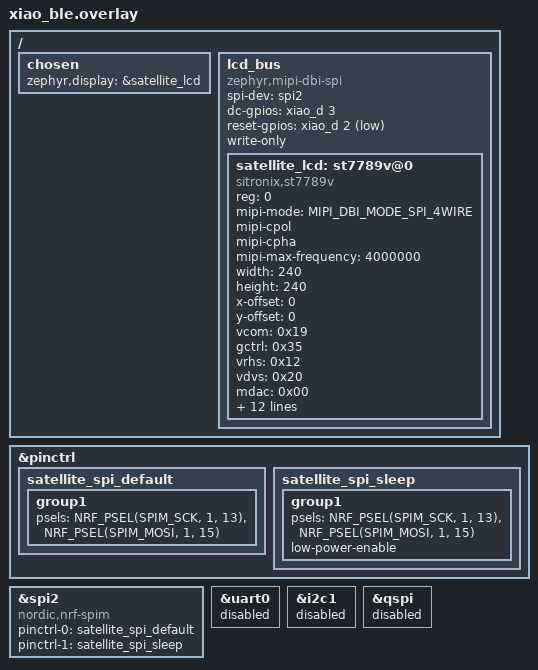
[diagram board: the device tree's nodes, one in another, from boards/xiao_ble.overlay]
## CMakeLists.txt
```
cmake_minimum_required(VERSION 3.20.0)
set(SATELLITE_STAGE "status" CACHE STRING "display, ble, or status")
if(SATELLITE_STAGE STREQUAL "ble")
  list(APPEND EXTRA_CONF_FILE "${CMAKE_CURRENT_SOURCE_DIR}/config/ble.conf")
  list(APPEND EXTRA_CONF_FILE "${CMAKE_CURRENT_SOURCE_DIR}/config/bluetooth.conf")
elseif(SATELLITE_STAGE STREQUAL "display" OR SATELLITE_STAGE STREQUAL "status")
  list(APPEND EXTRA_CONF_FILE "${CMAKE_CURRENT_SOURCE_DIR}/config/lvgl.conf")
  if(SATELLITE_STAGE STREQUAL "display")
    list(APPEND EXTRA_CONF_FILE "${CMAKE_CURRENT_SOURCE_DIR}/config/display.conf")
  else()
    list(APPEND EXTRA_CONF_FILE "${CMAKE_CURRENT_SOURCE_DIR}/config/bluetooth.conf")
  endif()
else()
  message(FATAL_ERROR "SATELLITE_STAGE must be display, ble or status")
endif()
find_package(Zephyr REQUIRED HINTS $ENV{ZEPHYR_BASE})
project(zmk_satellite VERSION 0.1.0 LANGUAGES C)
target_include_directories(app PRIVATE src)
target_sources(app PRIVATE src/main.c src/protocol.c src/state.c)
target_sources_ifdef(CONFIG_SATELLITE_BLE app PRIVATE src/scanner.c)
target_sources_ifdef(CONFIG_SATELLITE_DISPLAY app PRIVATE src/ui.c)
```

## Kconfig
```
mainmenu "ZMK Satellite"
source "Kconfig.zephyr"

config SATELLITE_DISPLAY
    bool "Enable ST7789 / LVGL display"
    default y
    select DISPLAY
    select LVGL

config SATELLITE_BLE
    bool "Receive Prospector-compatible advertisements"
    default y
    select BT
    select BT_OBSERVER

config SATELLITE_DISPLAY_TEST
    bool "Show color, border and simulated-state test (no live BLE)"
    default n
    depends on SATELLITE_DISPLAY && !SATELLITE_BLE

config SATELLITE_CHANNEL
    int "Prospector scanner channel (0 or >=10 accepts all, upstream semantics)"
    range 0 255
    default 0

config SATELLITE_KEYBOARD_ID
    string "Optional keyboard ID, 8 hexadecimal characters in wire order"
    default ""

config SATELLITE_KEYBOARD_NAME
    string "Optional display name override (ASCII)"
    default ""
    help
      Normally the keyboard name is learned from its BLE name advertisements.
      Set this only for a local display alias; it does not change the keyboard.

config SATELLITE_TIMEOUT_MS
    int "Advertisement silence timeout (must exceed keyboard idle interval)"
    range 1000 3600000
    default 95000
```

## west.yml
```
manifest:
  version: "0.13"
  self:
    path: zmk-satellite
  projects:
    - name: zephyr
      url: https://github.com/zephyrproject-rtos/zephyr
      revision: 7823374e872145b5bd018bfe447839eb36042611 # v4.1.0
      import:
        name-allowlist: [cmsis, cmsis_6, hal_nordic, lvgl, segger]
```

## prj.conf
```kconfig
CONFIG_MAIN_STACK_SIZE=4096
CONFIG_HEAP_MEM_POOL_SIZE=2048
CONFIG_LOG=y
CONFIG_LOG_MODE_DEFERRED=y
CONFIG_LOG_BUFFER_SIZE=4096
CONFIG_SERIAL=y
CONFIG_CONSOLE=y
CONFIG_UART_CONSOLE=y
CONFIG_USB_DEVICE_STACK=y
CONFIG_USB_CDC_ACM=y
CONFIG_USB_DEVICE_PRODUCT="ZMK Satellite"
CONFIG_USB_DEVICE_INITIALIZE_AT_BOOT=n
CONFIG_SPI=y
CONFIG_GPIO=y
CONFIG_ASSERT=y
```

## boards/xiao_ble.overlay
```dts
/*
 * SPDX-License-Identifier: Apache-2.0
 * ST7789 initialization values adapted from Zephyr's
 * st7789v_waveshare_240x240.overlay:
 * Copyright (c) 2019 Jan Van Winkel <jan.van_winkel@dxplore.eu>
 * Copyright (c) 2019 PHYTEC Messtechnik GmbH
 * SPI mode 3; no CS line (verified on the prototype panel). This bus must be dedicated to this panel.
 */
#include <zephyr/dt-bindings/gpio/gpio.h>
#include <zephyr/dt-bindings/pinctrl/nrf-pinctrl.h>
#include <zephyr/dt-bindings/mipi_dbi/mipi_dbi.h>

/ {
    chosen { zephyr,display = &satellite_lcd; };
    lcd_bus {
        compatible = "zephyr,mipi-dbi-spi";
        spi-dev = <&spi2>;
        dc-gpios = <&xiao_d 3 GPIO_ACTIVE_HIGH>;
        reset-gpios = <&xiao_d 2 GPIO_ACTIVE_LOW>;
        write-only;
        #address-cells = <1>;
        #size-cells = <0>;
        satellite_lcd: st7789v@0 {
            compatible = "sitronix,st7789v";
            reg = <0>;
            mipi-mode = "MIPI_DBI_MODE_SPI_4WIRE";
            mipi-cpol;
            mipi-cpha;
            mipi-max-frequency = <4000000>;
            width = <240>; height = <240>;
            x-offset = <0>; y-offset = <0>;
            vcom = <0x19>; gctrl = <0x35>;
            vrhs = <0x12>; vdvs = <0x20>;
            mdac = <0x00>; gamma = <0x01>;
            colmod = <0x05>; lcm = <0x2c>;
            porch-param = [0c 0c 00 33 33];
            cmd2en-param = [5a 69 02 01];
            pwctrl1-param = [a4 a1];
            pvgam-param = [d0 04 0d 11 13 2b 3f 54 4c 18 0d 0b 1f 23];
            nvgam-param = [d0 04 0c 11 13 2c 3f 44 51 2f 1f 1f 20 23];
            ram-param = [00 f8]; /* LVGL native little-endian RGB565 */ rgb-param = [cd 08 14];
        };
    };
};
&pinctrl {
    satellite_spi_default: satellite_spi_default {
        group1 { psels = <NRF_PSEL(SPIM_SCK, 1, 13)>,
                         <NRF_PSEL(SPIM_MOSI, 1, 15)>; };
    };
    satellite_spi_sleep: satellite_spi_sleep {
        group1 { psels = <NRF_PSEL(SPIM_SCK, 1, 13)>,
                         <NRF_PSEL(SPIM_MOSI, 1, 15)>;
                 low-power-enable; };
    };
};
&spi2 {
    compatible = "nordic,nrf-spim";
    status = "okay";
    pinctrl-0 = <&satellite_spi_default>;
    pinctrl-1 = <&satellite_spi_sleep>;
    pinctrl-names = "default", "sleep";
    /delete-property/ cs-gpios;
};
&uart0 { status = "disabled"; };
&i2c1 { status = "disabled"; };
&qspi { status = "disabled"; };
```

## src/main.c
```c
/* SPDX-License-Identifier: MIT */
#include "state.h"
#include <zephyr/kernel.h>
#include <zephyr/logging/log.h>
#include <zephyr/usb/usb_device.h>
#include <string.h>
#include <stdio.h>
#ifdef CONFIG_SATELLITE_BLE
#include "scanner.h"
#endif
#ifdef CONFIG_SATELLITE_DISPLAY
#include "ui.h"
#endif
LOG_MODULE_REGISTER(satellite, LOG_LEVEL_INF);

int main(void)
{
    int ret = usb_enable(NULL); /* Never wait for a host/DTR: USB-C power bank works. */
    if (ret) LOG_WRN("USB console unavailable: %d", ret);
    bool fatal = false;
    uint8_t filter[4];
    const uint8_t *filter_id = NULL;
    if (strlen(CONFIG_SATELLITE_KEYBOARD_ID)) {
        if (!sat_parse_id(CONFIG_SATELLITE_KEYBOARD_ID, filter)) {
            LOG_ERR("Invalid SATELLITE_KEYBOARD_ID (expected 8 hex chars)");
            fatal = true;
        } else filter_id = filter;
    }
#ifdef CONFIG_SATELLITE_DISPLAY
    ret = sat_ui_init();
    if (ret) { LOG_ERR("Display failed: %d", ret); return ret; }
    if (fatal) sat_ui_error("Invalid keyboard ID");
#endif
#ifdef CONFIG_SATELLITE_BLE
    if (!fatal) {
        ret = sat_scanner_start();
        if (ret) {
            LOG_ERR("BLE scan failed: %d", ret);
#ifdef CONFIG_SATELLITE_DISPLAY
            sat_ui_error("BLE start failed");
#endif
            fatal = true;
        }
    }
#endif
    struct sat_state state = {0};
    int64_t next_update = 0;
#ifdef CONFIG_SATELLITE_BLE
    int64_t next_diagnostics = 0;
#else
    ARG_UNUSED(filter_id);
#endif
    bool was_online = false;
    while (true) {
        int64_t now = k_uptime_get();
#ifdef CONFIG_SATELLITE_BLE
        struct sat_rx rx;
        if (now >= next_diagnostics) {
            LOG_INF("Scanning active; queue drops=%u", sat_scanner_dropped());
            next_diagnostics = now + 10000;
        }
        /* Bounded drain: a crowded RF environment cannot starve the display. */
        for (unsigned i = 0; !fatal && i < 16 && sat_scanner_take(&rx); ++i) {
            if (sat_update(&state, &rx.packet, rx.rssi, rx.time,
                           CONFIG_SATELLITE_CHANNEL, filter_id)) {
                if (rx.keyboard_name[0])
                    memcpy(state.keyboard_name, rx.keyboard_name, sizeof(state.keyboard_name));
                LOG_INF("ID=%02X%02X%02X%02X L=%u R=%u layer=%u(%s) BT=%u flags=%02x RSSI=%d",
                    rx.packet.id[0], rx.packet.id[1], rx.packet.id[2], rx.packet.id[3],
                    rx.packet.battery_left, rx.packet.battery_right, rx.packet.layer,
                    rx.packet.layer_name, rx.packet.profile + 1, rx.packet.flags, rx.rssi);
            }
        }
#endif
#ifdef CONFIG_SATELLITE_DISPLAY_TEST
        struct sat_packet p = {.version = 0x22, .battery_left = 76,
            .battery_right = 65, .role = 1, .profile = 2, .flags = 0x10,
            .layer = (now / 3000) % 5, .id = {0x12,0x34,0x56,0x78}};
        const char *demo_layers[] = {"BASE", "NAV", "NUM", "ADJ", "Auto"};
        snprintf(p.layer_name, sizeof(p.layer_name), "%s", demo_layers[p.layer]);
        const uint8_t demo_flags[] = {0x30, 0x20, 0x00, 0x08, 0x38};
        p.flags = demo_flags[(now / 3000) % 5];
        memcpy(state.keyboard_name, "Demo board", 11);
        /* 15s live simulation, then simulated loss; repeats every 25s. */
        if (now % 25000 < 15000)
            sat_update(&state, &p, -48, now, 0, NULL);
#endif
        if (now >= next_update && !fatal) {
            bool online = sat_online(&state, now, CONFIG_SATELLITE_TIMEOUT_MS);
            if (was_online && !online) LOG_WRN("Advertisement timeout; values are stale");
            was_online = online;
#ifdef CONFIG_SATELLITE_DISPLAY
            sat_ui_update(&state, now);
#endif
            next_update = now + 250;
        }
#ifdef CONFIG_SATELLITE_DISPLAY
        sat_ui_tick(); /* LVGL is owned exclusively by this thread. */
#endif
        k_sleep(K_MSEC(10));
    }
    return 0;
}
```

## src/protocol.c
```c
/* SPDX-License-Identifier: MIT */
#include "protocol.h"
#include <string.h>

bool sat_decode(const uint8_t *d, size_t n, struct sat_packet *out)
{
    if (!d || !out || n < SAT_PAYLOAD_SIZE || d[0] != 0xff || d[1] != 0xff ||
        d[2] != 0xab || d[3] != 0xcd) return false;
    /* v1 legacy or module-major 2. Future majors require a protocol review. */
    if (d[4] != 1 && (d[4] >> 4) != 2) return false;
    if (d[10] > 1 || (d[7] & 7) > 4) return false; /* ignore split peripherals */
    struct sat_packet p = {
        .version = d[4], .battery_left = d[5], .battery_right = d[12],
        .layer = d[6], .profile = d[7] & 7, .patch = (d[7] >> 3) & 7,
        .dev = (d[7] & 0x40) != 0, .connections = d[8], .flags = d[9],
        .role = d[10], .index = d[11], .aux = {d[13], d[14]},
        .modifiers = d[23], .wpm = d[24], .channel = d[25],
    };
    memcpy(p.id, d + 19, 4);
    /* Built-in font is ASCII. Do not let partial UTF-8/control bytes reach LVGL. */
    for (size_t i = 0; i < 4; ++i)
        p.layer_name[i] = d[15+i] == 0 ? 0 :
                            (d[15+i] >= 32 && d[15+i] <= 126 ? d[15+i] : '?');
    p.layer_name[4] = 0;
    *out = p;
    return true;
}

bool sat_parse_ad(const uint8_t *d, size_t n, struct sat_packet *out)
{
    if (!d || !out) return false;
    while (n) {
        size_t field = *d++;
        --n;
        if (!field) break;
        if (field > n) return false;
        if (d[0] == 0xff && sat_decode(d + 1, field - 1, out)) return true;
        d += field;
        n -= field;
    }
    return false;
}

bool sat_channel_matches(uint8_t scanner, uint8_t keyboard)
{
    return scanner == 0 || scanner >= 10 || keyboard == 0 || scanner == keyboard;
}

static int hex(char c)
{
    if (c >= '0' && c <= '9') return c - '0';
    if (c >= 'a' && c <= 'f') return c - 'a' + 10;
    if (c >= 'A' && c <= 'F') return c - 'A' + 10;
    return -1;
}

bool sat_parse_id(const char *s, uint8_t out[4])
{
    uint8_t id[4];
    if (!s || !out || strlen(s) != 8) return false;
    for (unsigned i = 0; i < 4; ++i) {
        int a = hex(s[i*2]), b = hex(s[i*2+1]);
        if (a < 0 || b < 0) return false;
        id[i] = (uint8_t)((a << 4) | b);
    }
    memcpy(out, id, 4);
    return true;
}

/* Names are separate AD reports. Keep parsing independent of the Bluetooth stack. */
bool sat_parse_name(const uint8_t *d, size_t n, char out[SAT_NAME_SIZE])
{
    if (!d || !out) return false;
    char name[SAT_NAME_SIZE] = {0};
    bool found = false, complete = false;
    while (n) {
        size_t field = *d++;
        --n;
        if (!field) break;
        if (field > n) return false;
        if ((d[0] == 0x08 || d[0] == 0x09) && field > 1 &&
            (!complete || d[0] == 0x09)) {
            size_t used = 0;
            for (size_t i = 1; i < field && used < SAT_NAME_SIZE - 1; ++i) {
                uint8_t c = d[i];
                if (!c) break;
                if (i + 2 < field && c == 0xef && d[i+1] == 0xbc && d[i+2] == 0xbf) {
                    name[used++] = '_'; /* Full-width underscore, common in keyboard names. */
                    i += 2;
                } else if (c >= 0x80) {
                    name[used++] = '?';
                    while (i + 1 < field && (d[i+1] & 0xc0) == 0x80) ++i;
                } else name[used++] = c >= 32 && c <= 126 ? (char)c : '?';
            }
            name[used] = 0;
            found = used > 0;
            complete = d[0] == 0x09;
        }
        d += field;
        n -= field;
    }
    if (found) memcpy(out, name, SAT_NAME_SIZE);
    return found;
}

enum sat_host_status sat_host_from_flags(uint8_t flags)
{
    bool usb = (flags & 0x08) != 0; /* HID-ready, not merely USB power. */
    bool ble = (flags & 0x10) != 0;
    return usb ? (ble ? SAT_HOST_BOTH : SAT_HOST_USB) :
                 (ble ? SAT_HOST_BLE : SAT_HOST_OFFLINE);
}

enum sat_bt_status sat_bt_from_flags(uint8_t flags)
{
    if (flags & 0x10) return SAT_BT_CONNECTED;
    return flags & 0x20 ? SAT_BT_PAIRED : SAT_BT_UNPAIRED;
}
```

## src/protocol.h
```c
/* SPDX-License-Identifier: MIT */
#pragma once
#include <stdbool.h>
#include <stddef.h>
#include <stdint.h>

#define SAT_PAYLOAD_SIZE 26
#define SAT_NAME_SIZE 32
enum sat_host_status { SAT_HOST_OFFLINE, SAT_HOST_BLE, SAT_HOST_USB, SAT_HOST_BOTH };
enum sat_host_status sat_host_from_flags(uint8_t flags);
enum sat_bt_status { SAT_BT_UNPAIRED, SAT_BT_PAIRED, SAT_BT_CONNECTED };
enum sat_bt_status sat_bt_from_flags(uint8_t flags);
bool sat_parse_name(const uint8_t *data, size_t len, char out[SAT_NAME_SIZE]);
struct sat_packet {
    uint8_t version, battery_left, battery_right, layer, profile;
    uint8_t connections, flags, role, index, aux[2], id[4];
    uint8_t modifiers, wpm, channel, patch;
    bool dev;
    char layer_name[5];
};
/* Decode bytes explicitly, without packed-struct casts or alignment assumptions. */
bool sat_decode(const uint8_t *data, size_t len, struct sat_packet *out);
bool sat_parse_ad(const uint8_t *data, size_t len, struct sat_packet *out);
bool sat_channel_matches(uint8_t scanner, uint8_t keyboard);
bool sat_parse_id(const char *text, uint8_t out[4]);
```

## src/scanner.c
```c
/* SPDX-License-Identifier: MIT */
#include "scanner.h"
#include <string.h>
#include <zephyr/kernel.h>
#include <zephyr/bluetooth/bluetooth.h>
#include <zephyr/sys/atomic.h>
#include <zephyr/logging/log.h>
LOG_MODULE_REGISTER(sat_scan, LOG_LEVEL_INF);
K_MSGQ_DEFINE(rx_queue, sizeof(struct sat_rx), 16, 8);
static atomic_t dropped;

/* Only valid status senders get cache entries; unrelated name beacons cannot evict them. */
static struct {
    bt_addr_le_t address;
    uint8_t id[4];
    char name[SAT_NAME_SIZE];
    int64_t last_seen;
    bool used;
} names[8];

static void receive(const bt_addr_le_t *addr, int8_t rssi, uint8_t type,
                    struct net_buf_simple *buf)
{
    ARG_UNUSED(type);
    struct sat_rx rx = {.rssi = rssi, .time = k_uptime_get()};
    bool packet = sat_parse_ad(buf->data, buf->len, &rx.packet) &&
        sat_channel_matches(CONFIG_SATELLITE_CHANNEL, rx.packet.channel);
    int entry = -1, oldest = 0;
    for (unsigned i = 0; i < ARRAY_SIZE(names); ++i) {
        if (names[i].used && !bt_addr_le_cmp(addr, &names[i].address)) entry = i;
        if (!names[i].used || names[i].last_seen < names[oldest].last_seen) oldest = i;
    }
    if (packet) {
        if (entry < 0) entry = oldest;
        if (!names[entry].used || bt_addr_le_cmp(addr, &names[entry].address) ||
            memcmp(names[entry].id, rx.packet.id, 4)) {
            memset(&names[entry], 0, sizeof(names[entry]));
            bt_addr_le_copy(&names[entry].address, addr);
            memcpy(names[entry].id, rx.packet.id, 4);
            names[entry].used = true;
        }
    }
    if (entry >= 0) {
        char name[SAT_NAME_SIZE];
        if (sat_parse_name(buf->data, buf->len, name))
            memcpy(names[entry].name, name, sizeof(name));
        names[entry].last_seen = rx.time;
    }
    if (packet) {
        memcpy(rx.keyboard_name, names[entry].name, sizeof(rx.keyboard_name));
        /* UI/state updates remain exclusively on the main thread. */
        if (k_msgq_put(&rx_queue, &rx, K_NO_WAIT)) atomic_inc(&dropped);
    }
}
int sat_scanner_start(void)
{
    int ret = bt_enable(NULL);
    if (ret) return ret;
    const struct bt_le_scan_param params = {
        .type = BT_LE_SCAN_TYPE_ACTIVE,
        .options = BT_LE_SCAN_OPT_NONE,
        .interval = 0x60, .window = 0x60,
    };
    return bt_le_scan_start(&params, receive);
}
bool sat_scanner_take(struct sat_rx *rx) { return k_msgq_get(&rx_queue, rx, K_NO_WAIT) == 0; }
unsigned sat_scanner_dropped(void) { return (unsigned)atomic_get(&dropped); }
```

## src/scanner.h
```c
#pragma once
#include "state.h"
struct sat_rx { struct sat_packet packet; int8_t rssi; int64_t time; char keyboard_name[SAT_NAME_SIZE]; };
int sat_scanner_start(void);
bool sat_scanner_take(struct sat_rx *rx);
unsigned sat_scanner_dropped(void);
```

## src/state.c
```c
/* SPDX-License-Identifier: MIT */
#include "state.h"
#include <string.h>
bool sat_online(const struct sat_state *s, int64_t now, int64_t timeout)
{
    return s->seen && now >= s->last_seen && now - s->last_seen < timeout;
}
bool sat_update(struct sat_state *s, const struct sat_packet *p, int8_t rssi,
                int64_t now, uint8_t channel, const uint8_t *filter_id)
{
    if (!sat_channel_matches(channel, p->channel)) return false;
    if (filter_id && memcmp(filter_id, p->id, 4)) return false;
    if (s->seen && memcmp(s->packet.id, p->id, 4)) return false;
    s->packet = *p;
    s->rssi = rssi;
    s->last_seen = now;
    s->seen = true;
    return true;
}
```

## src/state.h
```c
/* SPDX-License-Identifier: MIT */
#pragma once
#include "protocol.h"
struct sat_state {
    struct sat_packet packet;
    int64_t last_seen;
    int8_t rssi;
    bool seen;
    char keyboard_name[SAT_NAME_SIZE];
};
bool sat_online(const struct sat_state *s, int64_t now, int64_t timeout);
/* First ID stays selected, including after timeout. No mixing adjacent keyboards. */
bool sat_update(struct sat_state *s, const struct sat_packet *p, int8_t rssi,
                int64_t now, uint8_t channel, const uint8_t *filter_id);
```

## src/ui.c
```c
/* SPDX-License-Identifier: MIT */
#include "ui.h"
#include <stdio.h>
#include <errno.h>
#include <zephyr/device.h>
#include <zephyr/drivers/display.h>
#include <lvgl.h>
#include <lvgl_zephyr.h>

#define INK 0xe8eff3
#define DIM 0x9aafbb
#define CYAN 0x68bdd5
#define WARN 0xffb66e
#define USB_COLOR 0xf3bb76

static lv_obj_t *name, *status, *layer_number, *host, *host_icon, *endpoint_row;
static lv_obj_t *battery[2], *unit[2], *ring[2];

static lv_obj_t *label(lv_obj_t *parent, const char *text, int x, int y, int w,
                       const lv_font_t *font, uint32_t color)
{
    lv_obj_t *obj = lv_label_create(parent);
    lv_obj_set_pos(obj, x, y);
    lv_obj_set_width(obj, w);
    lv_label_set_long_mode(obj, LV_LABEL_LONG_DOT);
    lv_obj_set_style_text_font(obj, font, 0);
    lv_obj_set_style_text_color(obj, lv_color_hex(color), 0);
    lv_label_set_text(obj, text);
    return obj;
}

static lv_obj_t *center_label(lv_obj_t *parent, const char *text, int x, int y,
                              int w, const lv_font_t *font, uint32_t color)
{
    lv_obj_t *obj = label(parent, text, x, y, w, font, color);
    lv_obj_set_style_text_align(obj, LV_TEXT_ALIGN_CENTER, 0);
    return obj;
}

static lv_obj_t *battery_ring(lv_obj_t *screen, int x)
{
    lv_obj_t *obj = lv_arc_create(screen);
    lv_obj_remove_style_all(obj);
    lv_obj_set_pos(obj, x, 90);
    lv_obj_set_size(obj, 88, 88);
    lv_obj_remove_flag(obj, LV_OBJ_FLAG_CLICKABLE | LV_OBJ_FLAG_SCROLLABLE);
    lv_obj_set_style_arc_width(obj, 4, LV_PART_MAIN);
    lv_obj_set_style_arc_color(obj, lv_color_hex(0x30434e), LV_PART_MAIN);
    lv_obj_set_style_arc_opa(obj, LV_OPA_COVER, LV_PART_MAIN);
    lv_obj_set_style_arc_rounded(obj, false, LV_PART_MAIN);
    lv_obj_set_style_arc_width(obj, 4, LV_PART_INDICATOR);
    lv_obj_set_style_arc_color(obj, lv_color_hex(CYAN), LV_PART_INDICATOR);
    lv_obj_set_style_arc_opa(obj, LV_OPA_COVER, LV_PART_INDICATOR);
    lv_obj_set_style_arc_rounded(obj, false, LV_PART_INDICATOR);
    /* Full circle, clockwise from twelve o'clock. Zero has no indicator. */
    lv_arc_set_bg_angles(obj, 0, 360);
    lv_arc_set_rotation(obj, 270);
    lv_arc_set_range(obj, 0, 100);
    lv_arc_set_value(obj, 0);
    return obj;
}

int sat_ui_init(void)
{
    const struct device *dev = DEVICE_DT_GET(DT_CHOSEN(zephyr_display));
    if (!device_is_ready(dev)) return -ENODEV;
    int ret = lvgl_init();
    if (ret) return ret;
    lv_obj_t *screen = lv_screen_active();
    lv_obj_set_style_bg_color(screen, lv_color_hex(0x0d1820), 0);
    lv_obj_set_style_bg_opa(screen, LV_OPA_COVER, 0);
    lv_obj_set_style_border_width(screen, 0, 0);
    lv_obj_set_style_pad_all(screen, 0, 0);
    lv_obj_remove_flag(screen, LV_OBJ_FLAG_SCROLLABLE);
    lv_obj_t *brand = label(screen, "ZMK SATELLITE", 14, 14, 212,
                            &lv_font_montserrat_10, DIM);
    lv_obj_set_style_text_letter_space(brand, 1, 0);
    name = label(screen, "Keyboard", 14, 35, 212, &lv_font_montserrat_24, INK);

    /* Shared column centres at x=64 and x=176. */
    for (unsigned i = 0; i < 2; ++i) {
        int x = i ? 124 : 12;
        center_label(screen, i ? "RIGHT" : "LEFT", x, 76, 104,
                     &lv_font_montserrat_10, 0xa5b7c1);
        ring[i] = battery_ring(screen, x + 8);
        battery[i] = center_label(screen, "--", x + 10, 109, 84,
                                  &lv_font_montserrat_36, INK);
        unit[i] = center_label(screen, "%", x + 10, 148, 84,
                               &lv_font_montserrat_12, 0xa5b7c1);
        lv_obj_add_flag(unit[i], LV_OBJ_FLAG_HIDDEN);
    }

    center_label(screen, "LAYER", 12, 190, 104, &lv_font_montserrat_10, 0xa5b7c1);
    layer_number = center_label(screen, "--", 12, 204, 104,
                                &lv_font_montserrat_24, INK);
    status = center_label(screen, "WAITING", 124, 190, 104,
                          &lv_font_montserrat_10, CYAN);
    endpoint_row = lv_obj_create(screen);
    lv_obj_remove_style_all(endpoint_row);
    lv_obj_set_pos(endpoint_row, 124, 203);
    lv_obj_set_size(endpoint_row, 104, 29);
    lv_obj_remove_flag(endpoint_row, LV_OBJ_FLAG_SCROLLABLE | LV_OBJ_FLAG_CLICKABLE);
    lv_obj_set_flex_flow(endpoint_row, LV_FLEX_FLOW_ROW);
    lv_obj_set_flex_align(endpoint_row, LV_FLEX_ALIGN_CENTER,
                         LV_FLEX_ALIGN_CENTER, LV_FLEX_ALIGN_CENTER);
    lv_obj_set_style_pad_column(endpoint_row, 5, 0);
    /* Existing LVGL font symbols: Font Awesome notices are in licenses/. */
    host_icon = label(endpoint_row, LV_SYMBOL_BLUETOOTH, 0, 0, LV_SIZE_CONTENT,
                      &lv_font_montserrat_18, CYAN);
    lv_obj_add_flag(host_icon, LV_OBJ_FLAG_HIDDEN);
    host = label(endpoint_row, "--", 0, 0, LV_SIZE_CONTENT,
                 &lv_font_montserrat_24, DIM);
    lv_timer_handler();
    return display_blanking_off(dev);
}

void sat_ui_update(const struct sat_state *s, int64_t now)
{
    const char *title = CONFIG_SATELLITE_KEYBOARD_NAME[0] ?
        CONFIG_SATELLITE_KEYBOARD_NAME : s->keyboard_name[0] ? s->keyboard_name : "Keyboard";
    lv_label_set_text(name, title);
    if (!s->seen) return;
    bool online = sat_online(s, now, CONFIG_SATELLITE_TIMEOUT_MS);
    enum sat_host_status endpoint = sat_host_from_flags(s->packet.flags);
    enum sat_bt_status bt_state = sat_bt_from_flags(s->packet.flags);
    bool usb = endpoint == SAT_HOST_USB;
    char text[32];
    if (usb) snprintf(text, sizeof(text), "USB");
    else snprintf(text, sizeof(text), "BT%u", s->packet.profile + 1);
    lv_label_set_text(host, text);
    lv_label_set_text(host_icon, usb ? LV_SYMBOL_USB : LV_SYMBOL_BLUETOOTH);
    lv_obj_remove_flag(host_icon, LV_OBJ_FLAG_HIDDEN);
    lv_obj_set_style_text_color(host, lv_color_hex(online ? INK : DIM), 0);
    lv_obj_set_style_text_color(host_icon, lv_color_hex(!online ? DIM : usb ? USB_COLOR : CYAN), 0);
    const char *connection = endpoint == SAT_HOST_BOTH ? "BT + USB READY" :
        usb || bt_state == SAT_BT_CONNECTED ? "CONNECTED" :
        bt_state == SAT_BT_PAIRED ? "PAIRED / OFFLINE" : "NOT PAIRED";
    lv_label_set_text(status, online ? connection : "SIGNAL LOST");
    uint32_t state_color = !online ? WARN : bt_state == SAT_BT_UNPAIRED && !usb ? 0xbdadf6 :
                           endpoint == SAT_HOST_OFFLINE ? WARN : CYAN;
    lv_obj_set_style_text_color(status, lv_color_hex(state_color), 0);
    uint8_t values[2] = {s->packet.battery_left, s->packet.battery_right};
    for (unsigned i = 0; i < 2; ++i) {
        bool unknown = values[i] > 100 ||
            (i == 1 && s->packet.role == 0) ||
            (values[i] == 0 && (i == 1 || s->packet.role == 1));
        bool low = !unknown && values[i] <= 10;
        if (unknown) snprintf(text, sizeof(text), "--");
        else snprintf(text, sizeof(text), "%u", values[i]);
        lv_label_set_text(battery[i], text);
        lv_obj_set_style_text_color(battery[i], lv_color_hex(!online ? DIM : low ? WARN : INK), 0);
        if (unknown) lv_obj_add_flag(unit[i], LV_OBJ_FLAG_HIDDEN);
        else lv_obj_remove_flag(unit[i], LV_OBJ_FLAG_HIDDEN);
        lv_arc_set_value(ring[i], unknown ? 0 : values[i]);
        lv_obj_set_style_arc_color(ring[i], lv_color_hex(!online ? DIM : low ? WARN : CYAN),
                                   LV_PART_INDICATOR);
    }
    snprintf(text, sizeof(text), "%02u", s->packet.layer);
    lv_label_set_text(layer_number, text);
    lv_obj_set_style_text_color(layer_number, lv_color_hex(online ? INK : DIM), 0);
}

void sat_ui_error(const char *message)
{
    lv_label_set_text(status, message);
    lv_obj_set_style_text_color(status, lv_color_hex(WARN), 0);
}
void sat_ui_tick(void) { lv_timer_handler(); }
```

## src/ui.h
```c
#pragma once
#include "state.h"
int sat_ui_init(void);
void sat_ui_update(const struct sat_state *s, int64_t now);
void sat_ui_error(const char *message);
void sat_ui_tick(void);
```
